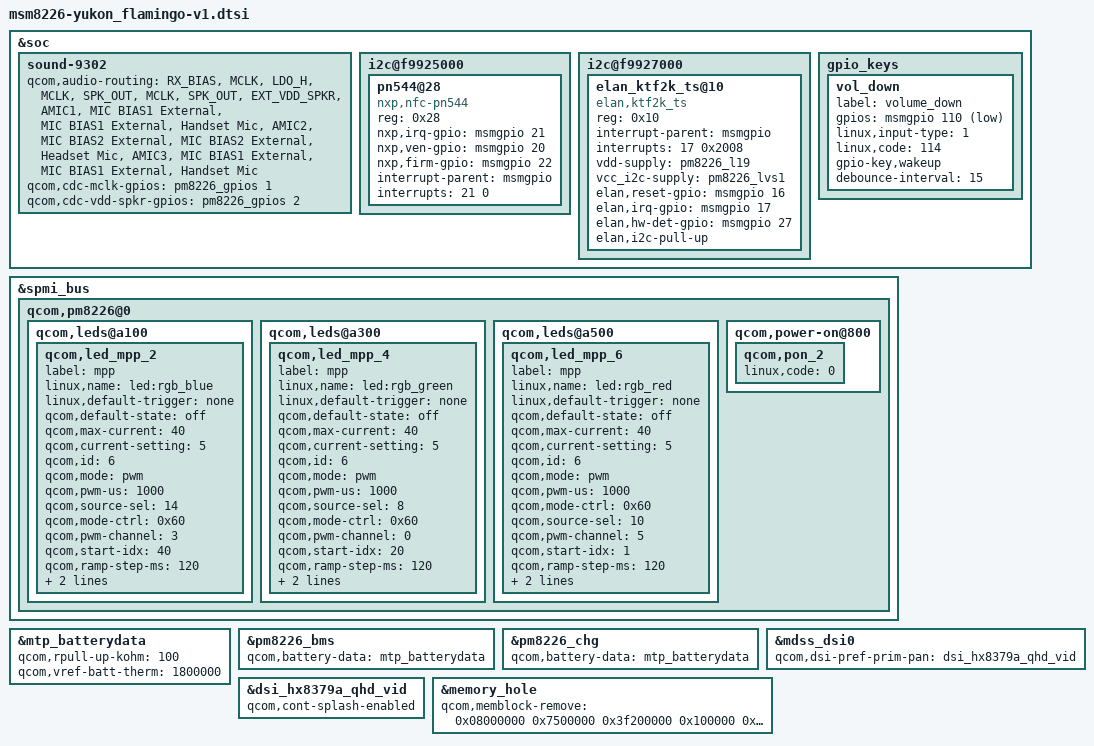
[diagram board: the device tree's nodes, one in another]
/include/ "msm8226-yukon_flamingo-mtp.dtsi"

/include/ "dsi-panel-truly-hx8379a-qhd-video.dtsi"

&soc {
	sound-9302 {
		qcom,audio-routing =
			"RX_BIAS", "MCLK",
			"LDO_H", "MCLK",
			"SPK_OUT", "MCLK",
			"SPK_OUT", "EXT_VDD_SPKR",
			"AMIC1", "MIC BIAS1 External",
			"MIC BIAS1 External", "Handset Mic",
			"AMIC2", "MIC BIAS2 External",
			"MIC BIAS2 External", "Headset Mic",
			"AMIC3", "MIC BIAS1 External",
			"MIC BIAS1 External", "Handset Mic";

		qcom,cdc-mclk-gpios = <&pm8226_gpios 1 0>;
		qcom,cdc-vdd-spkr-gpios = <&pm8226_gpios 2 0>;
	};
};

&soc {
		i2c@f9925000 { /* BLSP1 QUP3 */
		pn544@28 {
			compatible = "nxp,nfc-pn544";
			reg = <0x28>;
			nxp,irq-gpio = <&msmgpio 21 0x00>;
			nxp,ven-gpio = <&msmgpio 20 0x00>;
			nxp,firm-gpio = <&msmgpio 22 0x00>;
			interrupt-parent = <&msmgpio>;
			interrupts = <21 0>;
		};
	};
	i2c@f9927000 { /* BLSP1 QUP5 */
		elan_ktf2k_ts@10{
			compatible = "elan,ktf2k_ts";
			reg = <0x10>;
			interrupt-parent = <&msmgpio>;
			interrupts = <17 0x2008>;
			vdd-supply = <&pm8226_l19>;
			vcc_i2c-supply = <&pm8226_lvs1>;
			elan,reset-gpio = <&msmgpio 16 0x00>;
			elan,irq-gpio = <&msmgpio 17 0x2008>;
			elan,hw-det-gpio = <&msmgpio 27 0x00>;
			elan,i2c-pull-up;
		};
	};

	gpio_keys {
		vol_down {
			label = "volume_down";
			gpios = <&msmgpio 110 0x1>;
			linux,input-type = <1>;
			linux,code = <114>;
			gpio-key,wakeup;
			debounce-interval = <15>;
		};
	};
};

&spmi_bus {
	qcom,pm8226@0 {
		qcom,leds@a100 {
			status = "okay";
			qcom,led_mpp_2 {
				label = "mpp";
				linux,name = "led:rgb_blue";
				linux,default-trigger = "none";
				qcom,default-state = "off";
				qcom,max-current = <40>;
				qcom,current-setting = <5>;
				qcom,id = <6>;
				qcom,mode = "pwm";
				qcom,pwm-us = <1000>;
				qcom,source-sel = <14>;
				qcom,mode-ctrl = <0x60>;
				qcom,pwm-channel = <3>;
				qcom,start-idx = <40>;
				qcom,ramp-step-ms = <120>;
				qcom,duty-pcts = [00 00 50 99 99 99 50 00];
				qcom,use-blink;
			};
		};

		qcom,leds@a300 {
			status = "okay";
			qcom,led_mpp_4 {
				label = "mpp";
				linux,name = "led:rgb_green";
				linux,default-trigger = "none";
				qcom,default-state = "off";
				qcom,max-current = <40>;
				qcom,current-setting = <5>;
				qcom,id = <6>;
				qcom,mode = "pwm";
				qcom,pwm-us = <1000>;
				qcom,source-sel = <8>;
				qcom,mode-ctrl = <0x60>;
				qcom,pwm-channel = <0>;
				qcom,start-idx = <20>;
				qcom,ramp-step-ms = <120>;
				qcom,duty-pcts = [00 00 50 99 99 99 50 00];
				qcom,use-blink;
			};
		};

		qcom,leds@a500 {
			status = "okay";
			qcom,led_mpp_6 {
				label = "mpp";
				linux,name = "led:rgb_red";
				linux,default-trigger = "none";
				qcom,default-state = "off";
				qcom,max-current = <40>;
				qcom,current-setting = <5>;
				qcom,id = <6>;
				qcom,mode = "pwm";
				qcom,pwm-us = <1000>;
				qcom,mode-ctrl = <0x60>;
				qcom,source-sel = <10>;
				qcom,pwm-channel = <5>;
				qcom,start-idx = <1>;
				qcom,ramp-step-ms = <120>;
				qcom,duty-pcts = [00 00 50 99 99 99 50 00];
				qcom,use-blink;
			};
		};

		qcom,power-on@800 {
			qcom,pon_2 {
				linux,code = <0>;
			};
		};
	};
};

&mtp_batterydata {
	qcom,rpull-up-kohm = <100>;
	qcom,vref-batt-therm = <1800000>;
	/include/ "batterydata-yukon_flamingo.dtsi"
};

&pm8226_bms {
	qcom,battery-data = <&mtp_batterydata>;
};

&pm8226_chg {
	qcom,battery-data = <&mtp_batterydata>;
};

&mdss_dsi0 {
	qcom,dsi-pref-prim-pan = <&dsi_hx8379a_qhd_vid>;
};

&dsi_hx8379a_qhd_vid { 
	qcom,cont-splash-enabled;
};

&memory_hole {
	qcom,memblock-remove = <0x08000000 0x7500000
		0x3f200000 0x100000 // Add 1M from 0x3f200000 for restart_parameters
		0x0fa00000 0x500000>; /* Address and size of the hole */
};
